# GD32C211 register map
File version: 1.0
CPU: CM23 r0p0, little endian, MPU, FPU, 4 interrupt priority bits
Registers are 32-bit, read-write, reset 0x0 unless marked. A register's access mark holds for its fields unless they carry their own. Offsets are from the block's base; [hi:lo] are bit positions; {n}, {i} and the like mark numbered series; 'fields as' and 'values as' point back to an identical list.

## DMAMUX — DMAMUX controller
Base 0x40020800
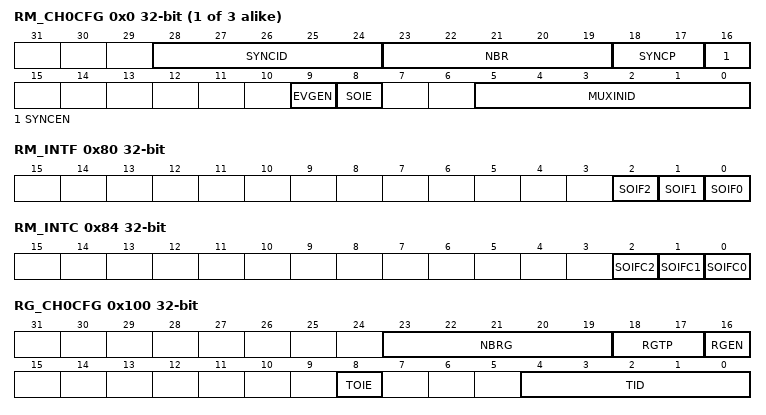
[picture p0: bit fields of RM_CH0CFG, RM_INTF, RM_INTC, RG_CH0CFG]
{0x0+4i} RM_CH{i}CFG (i=0..2) — Request multiplexer channel x configuration register
  [28:24] SYNCID — Synchronization input identification
  [23:19] NBR — Number of DMA requests to forward
  [18:17] SYNCP — Synchronization input polarity
  [16] SYNCEN — Synchronization enable
  [9] EVGEN — Event generation enable
  [8] SOIE — Synchronization overrun interrupt enable
  [5:0] MUXINID — Multiplexer input identification
0x80 RM_INTF ro — Request multiplexer channel interrupt flag register
  [2] SOIF2 — Synchronization overrun event flag of request multiplexer channel 2
  [1] SOIF1 — Synchronization overrun event flag of request multiplexer channel 1
  [0] SOIF0 — Synchronization overrun event flag of request multiplexer channel 0
0x84 RM_INTC wo — Request multiplexer channel interrupt flag clear register
  [2] SOIFC2 — Clear bit for synchronization overrun event flag of request multiplexer channel 2
  [1] SOIFC1 — Clear bit for synchronization overrun event flag of request multiplexer channel 1
  [0] SOIFC0 — Clear bit for synchronization overrun event flag of request multiplexer channel 0
0x100 RG_CH0CFG — Request generator channel x configuration register
  [23:19] NBRG — Number of DMA requests to be generated
  [18:17] RGTP — DMA request generator trigger polarity
  [16] RGEN — DMAMUX request generator channel x enable
  [8] TOIE — Trigger overrun interrupt enable
  [4:0] TID — Trigger input identification
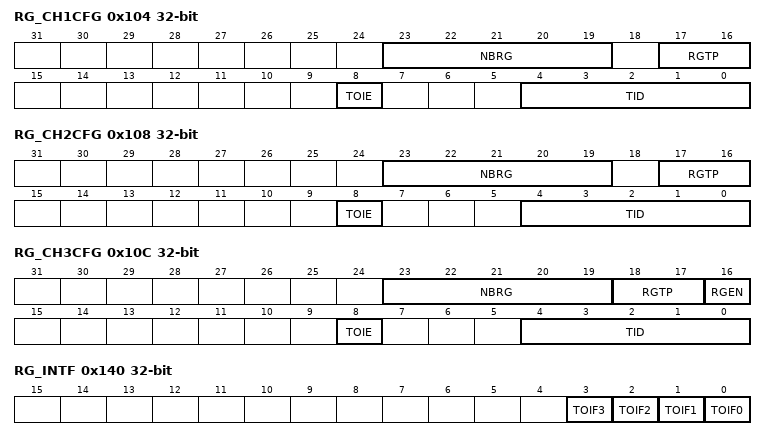
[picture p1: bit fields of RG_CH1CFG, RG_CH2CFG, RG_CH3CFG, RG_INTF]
0x104 RG_CH1CFG — Request generator channel 1 configuration register
  [23:19] NBRG — Number of DMA requests to be generated
  [17:16] RGTP — DMA request generator trigger polarity
  [8] TOIE — Trigger overrun interrupt enable
  [4:0] TID — Trigger input identification
0x108 RG_CH2CFG — Request generator channel 2 configuration register
  fields as RG_CH1CFG
0x10C RG_CH3CFG — Request generator channel x configuration register
  fields as RG_CH0CFG
0x140 RG_INTF ro — Request generator interrupt flag register
  [n] TOIF{n} (n=0..3) — Trigger overrun event flag of request generator channel {n}
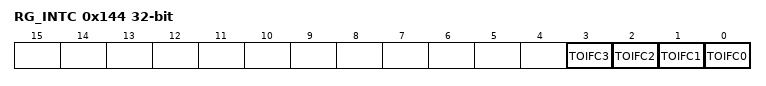
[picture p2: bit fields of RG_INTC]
0x144 RG_INTC ro — Rquest generator interrupt flag clear register
  [n] TOIFC{n} (n=0..3) — Clear bit for trigger overrun event flag of request generator channel {n}

## EXTI — Interrupt / event controller
Base 0x40010400
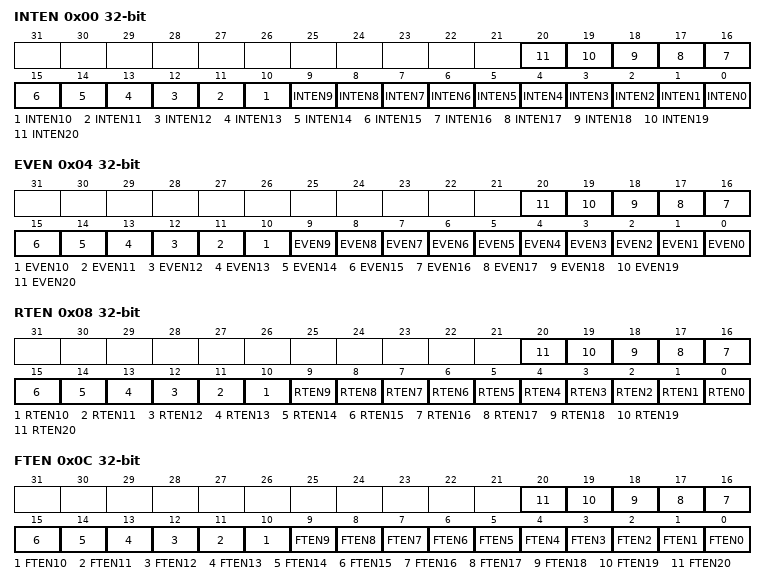
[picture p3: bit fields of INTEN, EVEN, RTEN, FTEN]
0x00 INTEN — Interrupt enable register
  [n] INTEN{n} (n=0..20) — Interrupt enable bit 24
0x04 EVEN — Event enable register
  [n] EVEN{n} (n=0..20) — Event enable bit 24
0x08 RTEN — Rising edge trigger enable register
  [n] RTEN{n} (n=0..20) — Rising edge trigger enable
0x0C FTEN — Falling edge trigger enable register
  [n] FTEN{n} (n=0..20) — Falling edge trigger enable
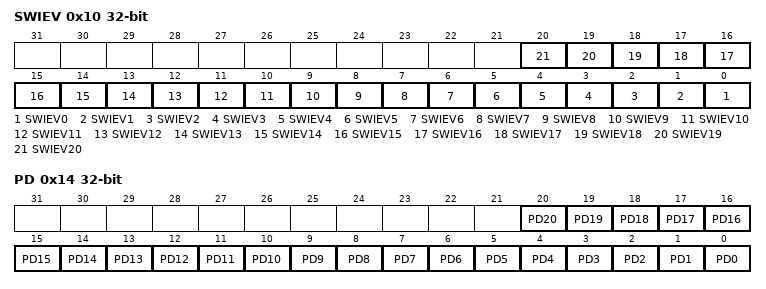
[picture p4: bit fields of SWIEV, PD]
0x10 SWIEV — Software interrupt event register
  [n] SWIEV{n} (n=0..20) — Interrupt / Event software trigger
0x14 PD — Pending register
  [n] PD{n} (n=0..20) — Interrupt pending status

## FMC — Flash memory controller
Base 0x40022000
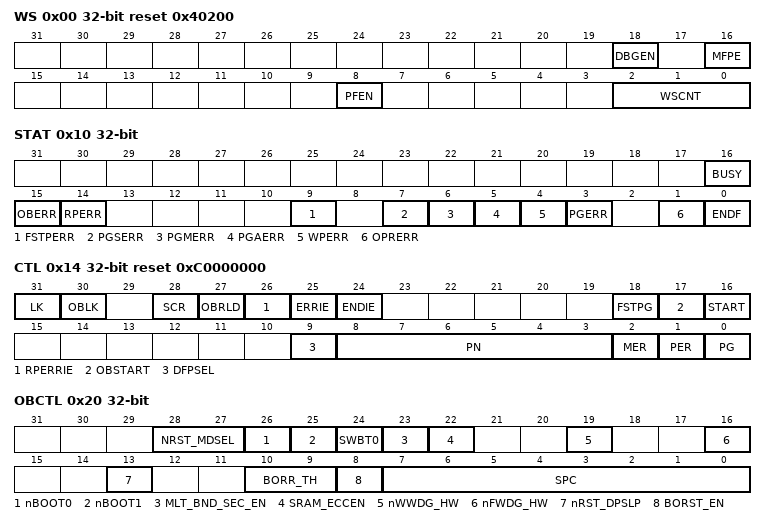
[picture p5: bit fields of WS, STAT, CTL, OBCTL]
0x00 WS reset 0x40200 — Wait state register
  [18] DBGEN — Debugger enable
  [16] MFPE — Main flash programmed or empty flag
  [8] PFEN — Pre-fetch enable
  [2:0] WSCNT — Wait state counter register
0x08 KEY wo — Unlock key register
  [31:0] KEY — FMC_CTL unlock register
0x0C OBKEY wo — Option byte unlock key register
  [31:0] OBKEY — FMC_CTL option bytes operation unlock register
0x10 STAT access per field — Status register
  [16] BUSY ro — The flash is busy bit
  [15] OBERR rw — Option byte read error bit.
  [14] RPERR rw — Read protection error flag bit.
  [9] FSTPERR rw — Fast programming error flag bit.
  [7] PGSERR rw — Program sequence error flag bit.
  [6] PGMERR rw — Program size not match error flag bit. This bit is set by hardware when program size is a half-word/word access. The only correct programming size is double word.
  [5] PGAERR rw — Program alignment error flag bit
  [4] WPERR rw — Erase / program protection error flag bit.
  [3] PGERR rw — Program error flag bit
  [1] OPRERR rw — Operation error flag bit
  [0] ENDF rw — End of operation flag bit
0x14 CTL reset 0xC0000000 — Control register
  [31] LK — FMC_CTL lock bit
  [30] OBLK — FMC_OBCTL lock bit
  [28] SCR — Secure-access area enable bit.
  [27] OBRLD — Option byte reload bit
  [26] RPERRIE — Read protection error interrupt enable bit
  [25] ERRIE — OPRERR error interrupt enable bit
  [24] ENDIE — End of operation interrupt enable bit
  [18] FSTPG — Main flash fast program command bit
  [17] OBSTART — Send option byte change command to FMC bit.
  [16] START — Send erase command to FMC bit
  [9] DFPSEL — Data flash page selection
  [8:3] PN — Page number selection
  [2] MER — Main flash mass erase command bit
  [1] PER — Main flash page erase command bit
  [0] PG — Main flash page program command bit
0x20 OBCTL — Option byte control register
  [28:27] NRST_MDSEL — NRST pin mode selection.
  [26] nBOOT0 — BOOT0 option bit
  [25] nBOOT1 — BOOT1 option bit
  [24] SWBT0 — Software BOOT0
  [23] MLT_BND_SEC_EN — Multiple-bonding security enable
  [22] SRAM_ECCEN — SRAM ECC disable
  [19] nWWDG_HW — Window watchdog configuration bit
  [16] nFWDG_HW — Free watchdog configuration bit
  [13] nRST_DPSLP — Option byte deepsleep reset value
  [10:9] BORR_TH — BOR threshold at rising VDD supply
  [8] BORST_EN — Brown out reset enable
  [7:0] SPC — Security protection level option byte status bits
0x24 DCRP_SADDR0 — DCRP start address register 0
  [5:0] DCRP0_SADDR — DCRP area 0 start address
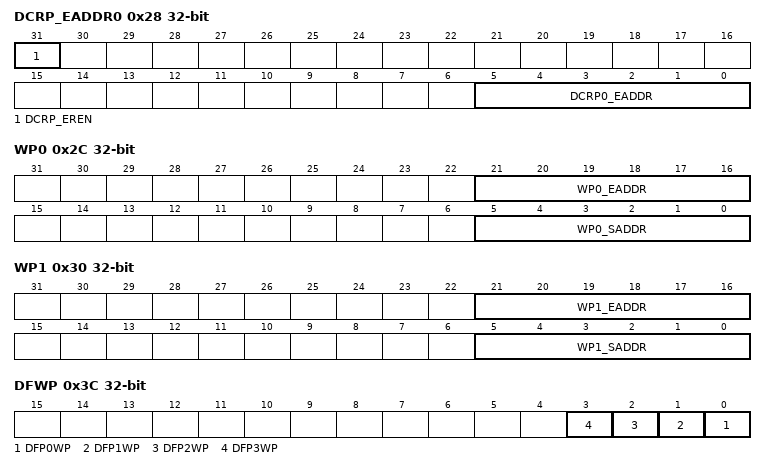
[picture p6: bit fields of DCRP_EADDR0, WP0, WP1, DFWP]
0x28 DCRP_EADDR0 — DCRP end address register
  [31] DCRP_EREN — DCRP area erase enable configuration bit.
  [5:0] DCRP0_EADDR — DCRP area 0 end address offset
0x2C WP0 — Write protection area 0 register
  [21:16] WP0_EADDR — Write protection area 0 end address offset
  [5:0] WP0_SADDR — Write protection area 0 end address offset
0x30 WP1 — Write protection area 1 register
  [21:16] WP1_EADDR — Write protection area 1 end address offset
  [5:0] WP1_SADDR — Write protection area 1 start address offset
0x34 DCRP_SADDR1 — DCRP start address register
  [5:0] DCRP1_SADDR — DCRP area 1 start address offset
0x38 DCRP_EADDR1 — DCRP end address register
  [5:0] DCRP1_EADDR — DCRP area 1 end address offset
0x3C DFWP — Data falsh write protection register
  [n] DFP{n}WP (n=0..3) — Data flash page {n} write protection config
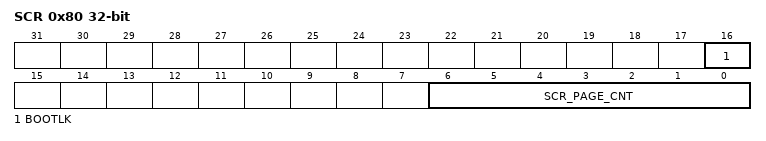
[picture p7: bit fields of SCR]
0x80 SCR — Secure user area register
  [16] BOOTLK — This bit is set to force boot from user Flash area.
  [6:0] SCR_PAGE_CNT — Configure the number of pages in secure user area.
